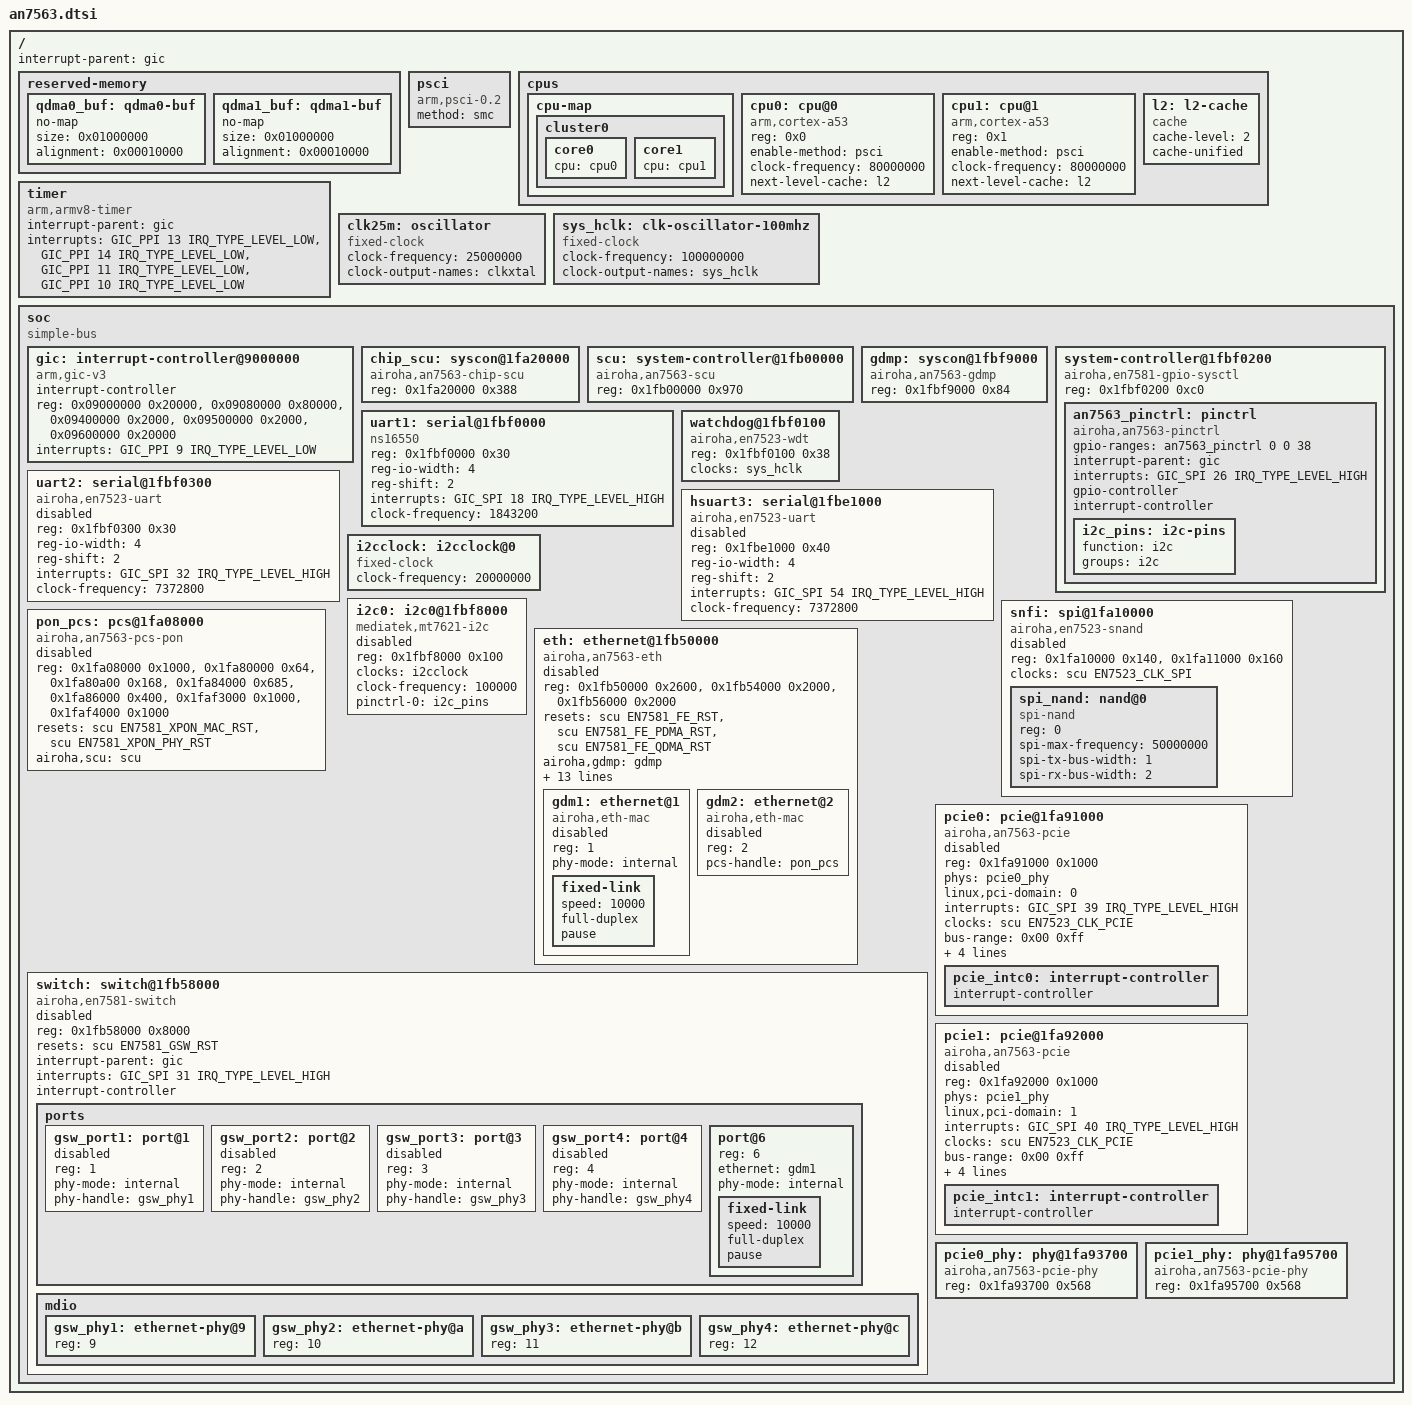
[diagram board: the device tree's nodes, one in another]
// SPDX-License-Identifier: (GPL-2.0-only OR BSD-2-Clause)
/*
 * Airoha AN7563 / AN7552 SoC dtsi.
 *
 * AN7563 boots a dual Cortex-A53 cluster in 32-bit AArch32 mode, but
 * its chip-SCU and SCU register windows match the EN7581 layout (the
 * IOMUX_1 register sits at chip-SCU offset 0x214, not 0x210 as on
 * EN7523). To share clk-en7523 / reset / pinctrl-airoha driver paths
 * with EN7581, the SCU nodes carry an AN7563-specific compatible
 * followed by the "airoha,en7581-{chip-,}scu" fallback compatible.
 */

#include <dt-bindings/interrupt-controller/irq.h>
#include <dt-bindings/interrupt-controller/arm-gic.h>
#include <dt-bindings/clock/en7523-clk.h>
#include <dt-bindings/reset/airoha,en7581-reset.h>
#include <dt-bindings/leds/common.h>

/ {
	interrupt-parent = <&gic>;
	#address-cells = <1>;
	#size-cells = <1>;

	reserved-memory {
		#address-cells = <1>;
		#size-cells = <1>;
		ranges;

		qdma0_buf: qdma0-buf {
			no-map;
			size = <0x01000000>;
			alignment = <0x00010000>;
		};

		qdma1_buf: qdma1-buf {
			no-map;
			size = <0x01000000>;
			alignment = <0x00010000>;
		};
	};

	psci {
		compatible = "arm,psci-0.2";
		method = "smc";
	};

	cpus {
		#address-cells = <1>;
		#size-cells = <0>;

		cpu-map {
			cluster0 {
				core0 {
					cpu = <&cpu0>;
				};

				core1 {
					cpu = <&cpu1>;
				};
			};
		};

		cpu0: cpu@0 {
			device_type = "cpu";
			compatible = "arm,cortex-a53";
			reg = <0x0>;
			enable-method = "psci";
			clock-frequency = <80000000>;
			next-level-cache = <&l2>;
		};

		cpu1: cpu@1 {
			device_type = "cpu";
			compatible = "arm,cortex-a53";
			reg = <0x1>;
			enable-method = "psci";
			clock-frequency = <80000000>;
			next-level-cache = <&l2>;
		};

		l2: l2-cache {
			compatible = "cache";
			cache-level = <2>;
			cache-unified;
		};
	};

	timer {
		compatible = "arm,armv8-timer";
		interrupt-parent = <&gic>;
		interrupts = <GIC_PPI 13 IRQ_TYPE_LEVEL_LOW>,
			     <GIC_PPI 14 IRQ_TYPE_LEVEL_LOW>,
			     <GIC_PPI 11 IRQ_TYPE_LEVEL_LOW>,
			     <GIC_PPI 10 IRQ_TYPE_LEVEL_LOW>;
	};

	clk25m: oscillator {
		compatible = "fixed-clock";
		#clock-cells = <0>;
		clock-frequency = <25000000>;
		clock-output-names = "clkxtal";
	};

	sys_hclk: clk-oscillator-100mhz {
		compatible = "fixed-clock";
		#clock-cells = <0>;
		clock-frequency = <100000000>;
		clock-output-names = "sys_hclk";
	};

	soc {
		compatible = "simple-bus";
		#address-cells = <1>;
		#size-cells = <1>;
		ranges;

		gic: interrupt-controller@9000000 {
			compatible = "arm,gic-v3";
			interrupt-controller;
			#interrupt-cells = <3>;
			#address-cells = <1>;
			#size-cells = <1>;
			reg = <0x09000000 0x20000>,
			      <0x09080000 0x80000>,
			      <0x09400000 0x2000>,
			      <0x09500000 0x2000>,
			      <0x09600000 0x20000>;
			interrupts = <GIC_PPI 9 IRQ_TYPE_LEVEL_LOW>;
		};

		chip_scu: syscon@1fa20000 {
			compatible = "airoha,an7563-chip-scu",
				     "airoha,en7581-chip-scu", "syscon";
			reg = <0x1fa20000 0x388>;
		};

		scu: system-controller@1fb00000 {
			compatible = "airoha,an7563-scu",
				     "airoha,en7581-scu", "syscon";
			reg = <0x1fb00000 0x970>;

			#clock-cells = <1>;
			#reset-cells = <1>;
		};

		gdmp: syscon@1fbf9000 {
			compatible = "airoha,an7563-gdmp", "syscon";
			reg = <0x1fbf9000 0x84>;
		};

		system-controller@1fbf0200 {
			compatible = "airoha,en7581-gpio-sysctl", "syscon",
				     "simple-mfd";
			reg = <0x1fbf0200 0xc0>;

			an7563_pinctrl: pinctrl {
				compatible = "airoha,an7563-pinctrl";
				gpio-ranges = <&an7563_pinctrl 0 0 38>;

				interrupt-parent = <&gic>;
				interrupts = <GIC_SPI 26 IRQ_TYPE_LEVEL_HIGH>;

				gpio-controller;
				#gpio-cells = <2>;

				interrupt-controller;
				#interrupt-cells = <2>;

				i2c_pins: i2c-pins {
					function = "i2c";
					groups = "i2c";
				};
			};
		};

		uart1: serial@1fbf0000 {
			compatible = "ns16550";
			reg = <0x1fbf0000 0x30>;
			reg-io-width = <4>;
			reg-shift = <2>;
			interrupts = <GIC_SPI 18 IRQ_TYPE_LEVEL_HIGH>;
			clock-frequency = <1843200>;
		};

		watchdog@1fbf0100 {
			compatible = "airoha,en7523-wdt";
			reg = <0x1fbf0100 0x38>;

			clocks = <&sys_hclk>;
			clock-names = "bus";
		};

		uart2: serial@1fbf0300 {
			compatible = "airoha,en7523-uart";
			reg = <0x1fbf0300 0x30>;
			reg-io-width = <4>;
			reg-shift = <2>;
			interrupts = <GIC_SPI 32 IRQ_TYPE_LEVEL_HIGH>;
			clock-frequency = <7372800>;

			status = "disabled";
		};

		hsuart3: serial@1fbe1000 {
			compatible = "airoha,en7523-uart";
			reg = <0x1fbe1000 0x40>;
			reg-io-width = <4>;
			reg-shift = <2>;
			interrupts = <GIC_SPI 54 IRQ_TYPE_LEVEL_HIGH>;
			clock-frequency = <7372800>;

			status = "disabled";
		};

		i2cclock: i2cclock@0 {
			#clock-cells = <0>;
			compatible = "fixed-clock";

			/* 20 MHz */
			clock-frequency = <20000000>;
		};

		i2c0: i2c0@1fbf8000 {
			compatible = "mediatek,mt7621-i2c";
			reg = <0x1fbf8000 0x100>;

			clocks = <&i2cclock>;

			/* 100 kHz */
			clock-frequency = <100000>;
			#address-cells = <1>;
			#size-cells = <0>;

			pinctrl-names = "default";
			pinctrl-0 = <&i2c_pins>;

			status = "disabled";
		};

		snfi: spi@1fa10000 {
			compatible = "airoha,en7523-snand", "airoha,en7581-snand";
			reg = <0x1fa10000 0x140>,
			      <0x1fa11000 0x160>;

			clocks = <&scu EN7523_CLK_SPI>;
			clock-names = "spi";

			#address-cells = <1>;
			#size-cells = <0>;

			status = "disabled";

			spi_nand: nand@0 {
				compatible = "spi-nand";
				reg = <0>;
				spi-max-frequency = <50000000>;
				spi-tx-bus-width = <1>;
				spi-rx-bus-width = <2>;
			};
		};

		pon_pcs: pcs@1fa08000 {
			compatible = "airoha,an7563-pcs-pon";
			reg = <0x1fa08000 0x1000>,
			      <0x1fa80000 0x64>,
			      <0x1fa80a00 0x168>,
			      <0x1fa84000 0x685>,
			      <0x1fa86000 0x400>,
			      <0x1faf3000 0x1000>,
			      <0x1faf4000 0x1000>;
			reg-names = "mac", "an", "pcs", "multi", "rate",
				    "phya", "pma";
			resets = <&scu EN7581_XPON_MAC_RST>,
				 <&scu EN7581_XPON_PHY_RST>;
			reset-names = "mac", "phy";
			airoha,scu = <&scu>;
			#pcs-cells = <0>;
			status = "disabled";
		};

		eth: ethernet@1fb50000 {
			compatible = "airoha,an7563-eth";
			reg = <0x1fb50000 0x2600>,
			      <0x1fb54000 0x2000>,
			      <0x1fb56000 0x2000>;
			reg-names = "fe", "qdma0", "qdma1";
			resets = <&scu EN7581_FE_RST>,
				 <&scu EN7581_FE_PDMA_RST>,
				 <&scu EN7581_FE_QDMA_RST>;
			reset-names = "fe", "pdma", "qdma";
			airoha,gdmp = <&gdmp>;
			airoha,scu = <&scu>;
			interrupts = <GIC_SPI 37 IRQ_TYPE_LEVEL_HIGH>,
				     <GIC_SPI 55 IRQ_TYPE_LEVEL_HIGH>,
				     <GIC_SPI 56 IRQ_TYPE_LEVEL_HIGH>,
				     <GIC_SPI 57 IRQ_TYPE_LEVEL_HIGH>,
				     <GIC_SPI 38 IRQ_TYPE_LEVEL_HIGH>,
				     <GIC_SPI 58 IRQ_TYPE_LEVEL_HIGH>,
				     <GIC_SPI 59 IRQ_TYPE_LEVEL_HIGH>,
				     <GIC_SPI 60 IRQ_TYPE_LEVEL_HIGH>,
				     <GIC_SPI 49 IRQ_TYPE_LEVEL_HIGH>,
				     <GIC_SPI 64 IRQ_TYPE_LEVEL_HIGH>;
			memory-region = <&qdma0_buf>, <&qdma1_buf>;
			memory-region-names = "qdma0-buf", "qdma1-buf";
			#address-cells = <1>;
			#size-cells = <0>;
			status = "disabled";

			gdm1: ethernet@1 {
				compatible = "airoha,eth-mac";
				reg = <1>;
				phy-mode = "internal";
				status = "disabled";

				fixed-link {
					speed = <10000>;
					full-duplex;
					pause;
				};
			};

			gdm2: ethernet@2 {
				compatible = "airoha,eth-mac";
				reg = <2>;
				pcs-handle = <&pon_pcs>;
				status = "disabled";
			};
		};

		switch: switch@1fb58000 {
			compatible = "airoha,en7581-switch";
			reg = <0x1fb58000 0x8000>;
			resets = <&scu EN7581_GSW_RST>;
			interrupt-parent = <&gic>;
			interrupts = <GIC_SPI 31 IRQ_TYPE_LEVEL_HIGH>;
			interrupt-controller;
			#interrupt-cells = <1>;
			#address-cells = <0>;
			status = "disabled";

			ports {
				#address-cells = <1>;
				#size-cells = <0>;

				gsw_port1: port@1 {
					reg = <1>;
					phy-mode = "internal";
					phy-handle = <&gsw_phy1>;
					status = "disabled";
				};

				gsw_port2: port@2 {
					reg = <2>;
					phy-mode = "internal";
					phy-handle = <&gsw_phy2>;
					status = "disabled";
				};

				gsw_port3: port@3 {
					reg = <3>;
					phy-mode = "internal";
					phy-handle = <&gsw_phy3>;
					status = "disabled";
				};

				gsw_port4: port@4 {
					reg = <4>;
					phy-mode = "internal";
					phy-handle = <&gsw_phy4>;
					status = "disabled";
				};

				port@6 {
					reg = <6>;
					ethernet = <&gdm1>;
					phy-mode = "internal";

					fixed-link {
						speed = <10000>;
						full-duplex;
						pause;
					};
				};
			};

			mdio: mdio {
				#address-cells = <1>;
				#size-cells = <0>;

				gsw_phy1: ethernet-phy@9 {
					reg = <9>;
				};

				gsw_phy2: ethernet-phy@a {
					reg = <10>;
				};

				gsw_phy3: ethernet-phy@b {
					reg = <11>;
				};

				gsw_phy4: ethernet-phy@c {
					reg = <12>;
				};
			};
		};

		pcie0: pcie@1fa91000 {
			compatible = "airoha,an7563-pcie", "mediatek,mt7622-pcie";
			device_type = "pci";
			reg = <0x1fa91000 0x1000>;
			reg-names = "port0";
			phys = <&pcie0_phy>;
			phy-names = "pcie-phy0";
			linux,pci-domain = <0>;
			#address-cells = <3>;
			#size-cells = <2>;
			interrupts = <GIC_SPI 39 IRQ_TYPE_LEVEL_HIGH>;
			interrupt-names = "pcie_irq";
			clocks = <&scu EN7523_CLK_PCIE>;
			clock-names = "sys_ck0";
			bus-range = <0x00 0xff>;
			ranges = <0x82000000 0 0x20000000 0x20000000 0 0x2000000>;

			status = "disabled";

			#interrupt-cells = <1>;
			interrupt-map-mask = <0 0 0 7>;
			interrupt-map = <0 0 0 1 &pcie_intc0 0>,
					<0 0 0 2 &pcie_intc0 1>,
					<0 0 0 3 &pcie_intc0 2>,
					<0 0 0 4 &pcie_intc0 3>;

			pcie_intc0: interrupt-controller {
				interrupt-controller;
				#address-cells = <0>;
				#interrupt-cells = <1>;
			};
		};

		pcie1: pcie@1fa92000 {
			compatible = "airoha,an7563-pcie", "mediatek,mt7622-pcie";
			device_type = "pci";
			reg = <0x1fa92000 0x1000>;
			reg-names = "port1";
			phys = <&pcie1_phy>;
			phy-names = "pcie-phy1";
			linux,pci-domain = <1>;
			#address-cells = <3>;
			#size-cells = <2>;
			interrupts = <GIC_SPI 40 IRQ_TYPE_LEVEL_HIGH>;
			interrupt-names = "pcie_irq";
			clocks = <&scu EN7523_CLK_PCIE>;
			clock-names = "sys_ck1";
			bus-range = <0x00 0xff>;
			ranges = <0x82000000 0 0x22000000 0x22000000 0 0x2000000>;

			status = "disabled";

			#interrupt-cells = <1>;
			interrupt-map-mask = <0 0 0 7>;
			interrupt-map = <0 0 0 1 &pcie_intc1 0>,
					<0 0 0 2 &pcie_intc1 1>,
					<0 0 0 3 &pcie_intc1 2>,
					<0 0 0 4 &pcie_intc1 3>;

			pcie_intc1: interrupt-controller {
				interrupt-controller;
				#address-cells = <0>;
				#interrupt-cells = <1>;
			};
		};

		pcie0_phy: phy@1fa93700 {
			compatible = "airoha,an7563-pcie-phy";
			reg = <0x1fa93700 0x568>;
			#phy-cells = <0>;
		};

		pcie1_phy: phy@1fa95700 {
			compatible = "airoha,an7563-pcie-phy";
			reg = <0x1fa95700 0x568>;
			#phy-cells = <0>;
		};
	};
};
